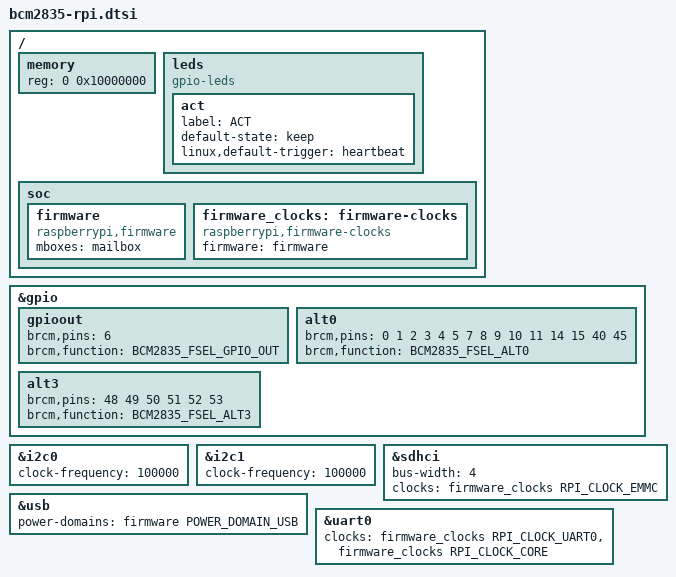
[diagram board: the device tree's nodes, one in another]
#include <dt-bindings/arm/raspberrypi-firmware-power.h>
#include <dt-bindings/clk/raspberrypi.h>
#include "bcm2835.dtsi"

/ {
	memory {
		reg = <0 0x10000000>;
	};

	leds {
		compatible = "gpio-leds";

		act {
			label = "ACT";
			default-state = "keep";
			linux,default-trigger = "heartbeat";
		};
	};

	soc {
		firmware: firmware {
			compatible = "raspberrypi,firmware";
			mboxes = <&mailbox>;
			#power-domain-cells = <1>;
		};

		firmware_clocks: firmware-clocks {
			compatible = "raspberrypi,firmware-clocks";
			#clock-cells = <1>;
			firmware = <&firmware>;
		};
	};
};

&gpio {
	pinctrl-names = "default";

	gpioout: gpioout {
		brcm,pins = <6>;
		brcm,function = <BCM2835_FSEL_GPIO_OUT>;
	};

	alt0: alt0 {
		brcm,pins = <0 1 2 3 4 5 7 8 9 10 11 14 15 40 45>;
		brcm,function = <BCM2835_FSEL_ALT0>;
	};

	alt3: alt3 {
		brcm,pins = <48 49 50 51 52 53>;
		brcm,function = <BCM2835_FSEL_ALT3>;
	};
};

&i2c0 {
	status = "okay";
	clock-frequency = <100000>;
};

&i2c1 {
	status = "okay";
	clock-frequency = <100000>;
};

&sdhci {
	status = "okay";
	bus-width = <4>;
	clocks = <&firmware_clocks RPI_CLOCK_EMMC>;
};

&usb {
	power-domains = <&firmware POWER_DOMAIN_USB>;
};

&uart0 {
	clocks = <&firmware_clocks RPI_CLOCK_UART0>,
		 <&firmware_clocks RPI_CLOCK_CORE>;
	clock-names = "uartclk", "apb_pclk";
};
